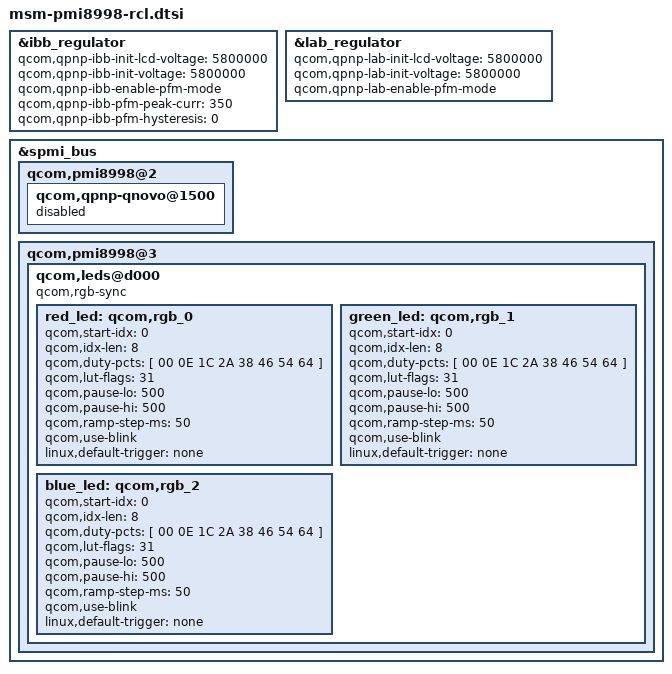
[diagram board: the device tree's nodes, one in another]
/* Copyright (c) 2016-2017, The Linux Foundation. All rights reserved.
 *
 * This program is free software; you can redistribute it and/or modify
 * it under the terms of the GNU General Public License version 2 and
 * only version 2 as published by the Free Software Foundation.
 *
 * This program is distributed in the hope that it will be useful,
 * but WITHOUT ANY WARRANTY; without even the implied warranty of
 * MERCHANTABILITY or FITNESS FOR A PARTICULAR PURPOSE.  See the
 * GNU General Public License for more details.
 */

/* Display */
&ibb_regulator {
	qcom,qpnp-ibb-init-lcd-voltage = <5800000>;
	qcom,qpnp-ibb-init-voltage = <5800000>;
	qcom,qpnp-ibb-enable-pfm-mode;
	qcom,qpnp-ibb-pfm-peak-curr = <350>;
	qcom,qpnp-ibb-pfm-hysteresis = <0>;
};

&lab_regulator {
	qcom,qpnp-lab-init-lcd-voltage = <5800000>;
	qcom,qpnp-lab-init-voltage = <5800000>;
	qcom,qpnp-lab-enable-pfm-mode;
};

&spmi_bus {
	qcom,pmi8998@2 {
		qcom,qpnp-qnovo@1500 {
			status = "disabled";
		};
	};

	qcom,pmi8998@3 {
		qcom,leds@d000 {
			qcom,rgb-sync;

			red_led: qcom,rgb_0 {
				qcom,start-idx = <0>;
				qcom,idx-len = <8>;
				qcom,duty-pcts = [ 00 0E 1C 2A 38 46 54 64 ];
				qcom,lut-flags = <31>; /* loop, ramp up, reverse, pause hi, pause lo */
				qcom,pause-lo = <500>;
				qcom,pause-hi = <500>;
				qcom,ramp-step-ms = <50>;
				qcom,use-blink;
				linux,default-trigger = "none";
			};

			green_led: qcom,rgb_1 {
				qcom,start-idx = <0>;
				qcom,idx-len = <8>;
				qcom,duty-pcts = [ 00 0E 1C 2A 38 46 54 64 ];
				qcom,lut-flags = <31>; /* loop, ramp up, reverse, pause hi, pause lo */
				qcom,pause-lo = <500>;
				qcom,pause-hi = <500>;
				qcom,ramp-step-ms = <50>;
				qcom,use-blink;
				linux,default-trigger = "none";
			};

			blue_led: qcom,rgb_2 {
				qcom,start-idx = <0>;
				qcom,idx-len = <8>;
				qcom,duty-pcts = [ 00 0E 1C 2A 38 46 54 64 ];
				qcom,lut-flags = <31>; /* loop, ramp up, reverse, pause hi, pause lo */
				qcom,pause-lo = <500>;
				qcom,pause-hi = <500>;
				qcom,ramp-step-ms = <50>;
				qcom,use-blink;
				linux,default-trigger = "none";
			};
		};
	};
};
